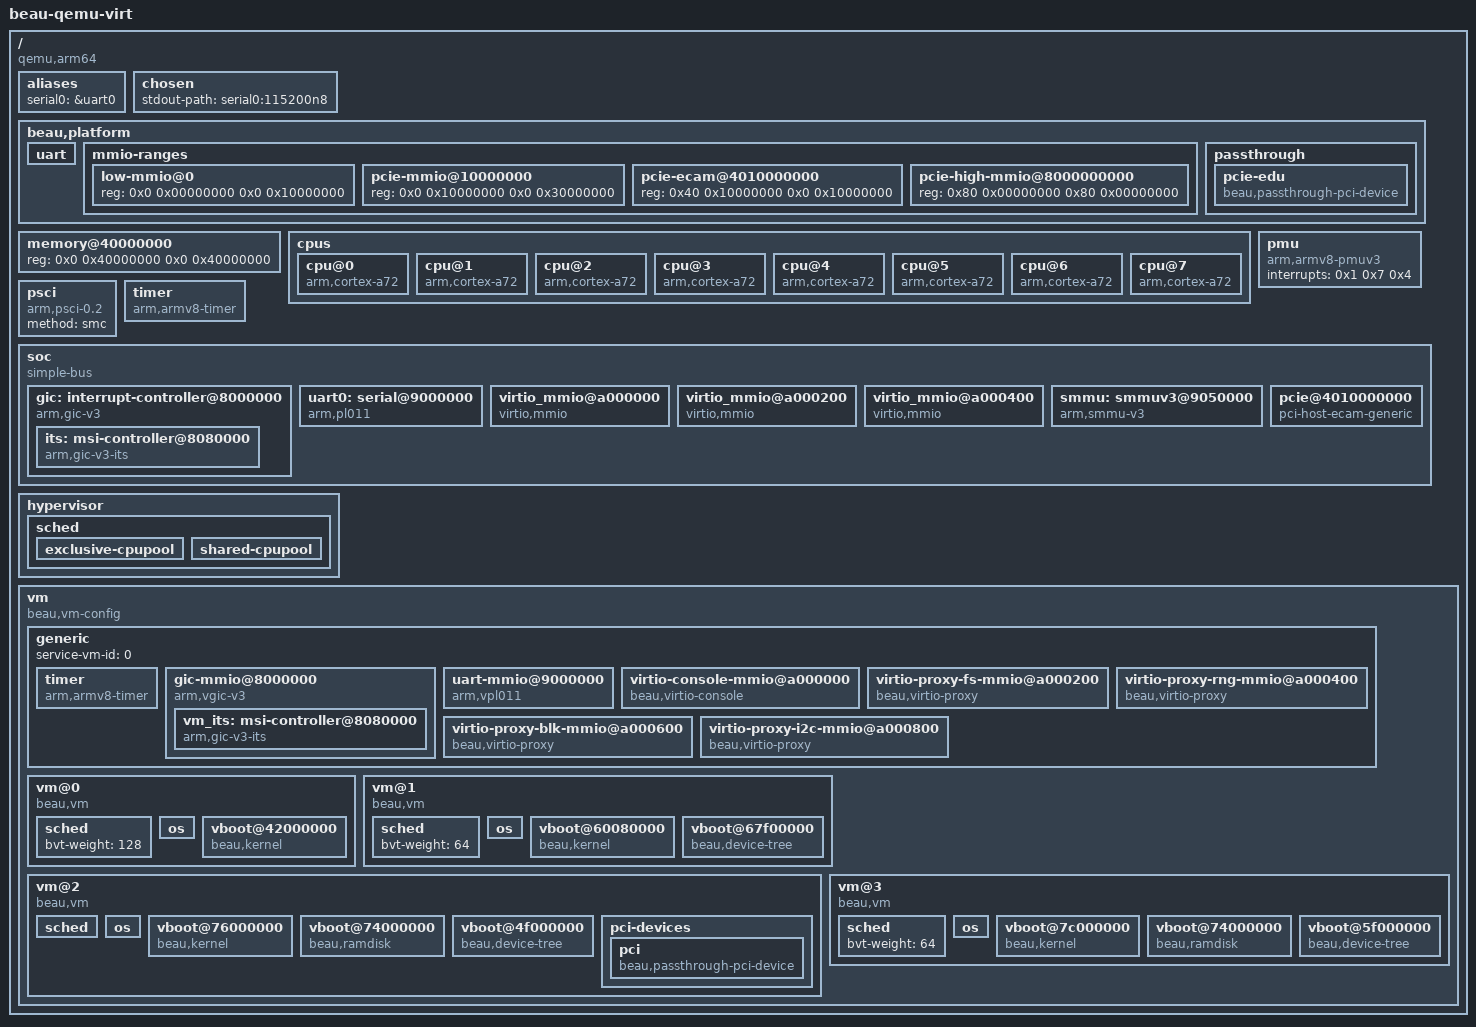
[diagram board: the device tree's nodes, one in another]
/dts-v1/;

/ {
	interrupt-parent = <&gic>;
	#address-cells = <2>;
	#size-cells = <2>;
	compatible = "qemu,arm64", "beau,qemu-static-config";
	model = "beau-qemu-virt";

	aliases {
		serial0 = &uart0;
	};

	chosen {
		stdout-path = "serial0:115200n8";
	};

	beau,platform {
		gic-iidr = <0x43b>;
		guest-cpu-compatible = "arm,cortex-a57";
		vfdt-model = "linux,dummy-virt";
		vfdt-compatible = "linux,dummy-virt";
		service-vm-initrd = <0>;

		uart {
			clock-frequency = <24000000>;
			current-speed = <115200>;
		};

		mmio-ranges {
			#address-cells = <2>;
			#size-cells = <2>;

			low-mmio@0 {
				reg = <0x0 0x00000000 0x0 0x10000000>;
			};

			pcie-mmio@10000000 {
				reg = <0x0 0x10000000 0x0 0x30000000>;
			};

			pcie-ecam@4010000000 {
				reg = <0x40 0x10000000 0x0 0x10000000>;
			};

			pcie-high-mmio@8000000000 {
				reg = <0x80 0x00000000 0x80 0x00000000>;
			};
		};

		passthrough {
			pcie-edu {
				compatible = "beau,passthrough-pci-device",
					     "beau,passthrough-device";
				beau,name = "qemu-pcie-edu";
				beau,owner-vm = <2>;
				beau,stream-id = <0x0008>;
				beau,writable;
			};
		};
	};

	memory@40000000 {
		device_type = "memory";
		reg = <0x0 0x40000000 0x0 0x40000000>;
	};

	cpus {
		#address-cells = <1>;
		#size-cells = <0>;

		cpu@0 {
			device_type = "cpu";
			compatible = "arm,cortex-a72";
			reg = <0>;
			enable-method = "psci";
		};

		cpu@1 {
			device_type = "cpu";
			compatible = "arm,cortex-a72";
			reg = <1>;
			enable-method = "psci";
		};

		cpu@2 {
			device_type = "cpu";
			compatible = "arm,cortex-a72";
			reg = <2>;
			enable-method = "psci";
		};

		cpu@3 {
			device_type = "cpu";
			compatible = "arm,cortex-a72";
			reg = <3>;
			enable-method = "psci";
		};

		cpu@4 {
			device_type = "cpu";
			compatible = "arm,cortex-a72";
			reg = <4>;
			enable-method = "psci";
		};

		cpu@5 {
			device_type = "cpu";
			compatible = "arm,cortex-a72";
			reg = <5>;
			enable-method = "psci";
		};

		cpu@6 {
			device_type = "cpu";
			compatible = "arm,cortex-a72";
			reg = <6>;
			enable-method = "psci";
		};

		cpu@7 {
			device_type = "cpu";
			compatible = "arm,cortex-a72";
			reg = <7>;
			enable-method = "psci";
		};
	};

	pmu {
		compatible = "arm,armv8-pmuv3";
		interrupts = <0x1 0x7 0x4>;
	};

	psci {
		compatible = "arm,psci-0.2";
		method = "smc";
	};

	timer {
		compatible = "arm,armv8-timer";
		interrupts = <0x1 0xd 0x4>,
			     <0x1 0xe 0x4>,
			     <0x1 0xb 0x4>,
			     <0x1 0xa 0x4>;
	};

	soc {
		compatible = "simple-bus";
		#address-cells = <2>;
		#size-cells = <2>;
		ranges;

		gic: interrupt-controller@8000000 {
			compatible = "arm,gic-v3", "arm,gic";
			reg = <0x0 0x08000000 0x0 0x00010000>,
			      <0x0 0x080a0000 0x0 0x00100000>;
			interrupts = <0x1 0x9 0x4>;
			interrupt-controller;
			#interrupt-cells = <3>;
			#address-cells = <2>;
			#size-cells = <2>;
			ranges;

			its: msi-controller@8080000 {
				compatible = "arm,gic-v3-its";
				reg = <0x0 0x08080000 0x0 0x00020000>;
				msi-controller;
			};
		};

		uart0: serial@9000000 {
			compatible = "arm,pl011", "arm,primecell";
			reg = <0x0 0x09000000 0x0 0x00001000>;
			interrupts = <0x0 0x1 0x4>;
			clock-frequency = <24000000>;
		};

		virtio_mmio@a000000 {
			compatible = "virtio,mmio";
			reg = <0x0 0x0a000000 0x0 0x00000200>;
			interrupts = <0x0 0x10 0x1>;
			dma-coherent;
		};

		virtio_mmio@a000200 {
			compatible = "virtio,mmio";
			reg = <0x0 0x0a000200 0x0 0x00000200>;
			interrupts = <0x0 0x11 0x1>;
			dma-coherent;
		};

		virtio_mmio@a000400 {
			compatible = "virtio,mmio";
			reg = <0x0 0x0a000400 0x0 0x00000200>;
			interrupts = <0x0 0x12 0x1>;
			dma-coherent;
		};

		smmu: smmuv3@9050000 {
			compatible = "arm,smmu-v3";
			reg = <0x0 0x09050000 0x0 0x00020000>;
			interrupts = <0x0 0x4a 0x4>,
				     <0x0 0x4b 0x4>,
				     <0x0 0x4c 0x4>,
				     <0x0 0x4d 0x4>;
			#iommu-cells = <1>;
		};

		pcie@4010000000 {
			compatible = "pci-host-ecam-generic";
			device_type = "pci";
			#address-cells = <3>;
			#size-cells = <2>;
			reg = <0x40 0x10000000 0x0 0x10000000>;
			bus-range = <0x0 0xff>;
			msi-map = <0x0 &its 0x0 0x10000>;
			iommu-map = <0x0 &smmu 0x0 0x10000>;
			dma-coherent;
			ranges = <0x01000000 0x0 0x00000000 0x0 0x3eff0000 0x0 0x00010000>,
				 <0x02000000 0x0 0x10000000 0x0 0x10000000 0x0 0x2eff0000>,
				 <0x03000000 0x80 0x00000000 0x80 0x00000000 0x80 0x00000000>;
		};
	};

	hypervisor {
		sched {
			exclusive-cpupool {
				pcpus = <0 1 4 5>;
				policy = "bvt";
			};
			shared-cpupool {
				pcpus = <2 3 6 7>;
				policy = "cbs";
				period = <3000>;
				budget = <1000>;
			};
		};
	};

	vm {
		compatible = "beau,vm-config";
		#address-cells = <1>;
		#size-cells = <0>;

		// Generic VM configuration
		generic {
			#address-cells = <2>;
			#size-cells = <2>;
			service-vm-id = <0>;

			timer {
				compatible = "arm,armv8-timer";
				// Hypervisor Timer
				htimer-ppi = <26>;
				// Virtual Timer
				vtimer-ppi = <27>;
				// Physical Timer
				ptimer-ppi = <30>;
			};

			gic-mmio@8000000 {
				compatible = "arm,vgic-v3";
				reg = <0x0 0x08000000 0x0 0x00010000>,
					  <0x0 0x080a0000 0x0 0x00100000>;
				interrupts = <0x1 0x9 0x4>;
				interrupt-controller;
				#interrupt-cells = <3>;
				#address-cells = <2>;
				#size-cells = <2>;
				ranges;

				vm_its: msi-controller@8080000 {
					compatible = "arm,gic-v3-its";
					reg = <0x0 0x08080000 0x0 0x00020000>;
					msi-controller;
				};
			};

			/*
			 * Guest console frontend policy:
			 *   RTOS  <- vPL011
			 *   Linux <- virtio-console
			 */
			uart-mmio@9000000 {
				compatible = "arm,vpl011";
				reg = <0x0 0x09000000 0x0 0x00001000>;
				interrupts = <0x0 0x1 0x4>;
				clock-frequency = <24000000>;
			};

			virtio-console-mmio@a000000 {
				compatible = "beau,virtio-console", "virtio,mmio";
				reg = <0x0 0x0a000000 0x0 0x00000200>;
				interrupts = <0x0 0x10 0x4>;
			};

			virtio-proxy-fs-mmio@a000200 {
				compatible = "beau,virtio-proxy", "beau,virtio-fs", "virtio,mmio";
				reg = <0x0 0x0a000200 0x0 0x00000200>;
				interrupts = <0x0 0x11 0x4>;
				beau,device-id = <26>;
				beau,frontend-vmid = <3>;
				beau,queue-num = <2>;
				beau,queue-size = <64>;
				beau,pending-num = <4>;
				beau,tag = "proxy-fs";
				beau,throughput = "high";
			};

			virtio-proxy-rng-mmio@a000400 {
				compatible = "beau,virtio-proxy", "beau,virtio-rng", "virtio,mmio";
				reg = <0x0 0x0a000400 0x0 0x00000200>;
				interrupts = <0x0 0x12 0x4>;
				beau,device-id = <4>;
				beau,frontend-vmid = <3>;
				beau,queue-num = <1>;
				beau,queue-size = <64>;
				beau,pending-num = <1>;
				beau,tag = "proxy-rng";
				beau,throughput = "low";
			};

			virtio-proxy-blk-mmio@a000600 {
				compatible = "beau,virtio-proxy", "beau,virtio-blk", "virtio,mmio";
				reg = <0x0 0x0a000600 0x0 0x00000200>;
				interrupts = <0x0 0x13 0x4>;
				beau,device-id = <2>;
				beau,frontend-vmid = <3>;
				beau,queue-num = <1>;
				beau,queue-size = <64>;
				beau,pending-num = <4>;
				beau,tag = "proxy-blk";
				beau,throughput = "high";
			};

			virtio-proxy-i2c-mmio@a000800 {
				compatible = "beau,virtio-proxy", "beau,virtio-i2c", "virtio,mmio";
				reg = <0x0 0x0a000800 0x0 0x00000200>;
				interrupts = <0x0 0x14 0x4>;
				beau,device-id = <34>;
				beau,frontend-vmid = <3>;
				beau,queue-num = <1>;
				beau,queue-size = <64>;
				beau,pending-num = <1>;
				beau,tag = "proxy-i2c";
				beau,throughput = "low";
			};
		};

		/*
		 * 2026-07-08, QEMU cpu-affinity is ordered: entry N is vcpuN's pCPU.
		 * This 4OS layout keeps vCPU0 on an exclusive pCPU and maps
		 * secondary vCPUs to shared pCPUs. VM0 and VM1 intentionally have
		 * 2 vCPUs.
		 */
		vm@0 {
			compatible = "beau,vm";
			reg = <0>;
			#address-cells = <2>;
			#size-cells = <2>;
			beau,name = "Zephyr";
			load-order = "service";
			beau,static-mem = <0x0 0x42000000 0x0 0x06000000>;
			direct-map;
			cpu-affinity = <0 2>;
			guest-flags = "static", "no-fw";
			beau,sve = "disabled";

			sched {
				bvt-weight = <128>;
			};

			os {
				os-name = "Zephyr";
				family = "rtos";
			};

			vboot@42000000 {
				compatible = "beau,kernel", "beau,vboot";
				tag = "Zephyr";
				source = "symbol";
				addr-symbol = "arm64_zephyr_image_start";
				size-source = "symbol";
				size-symbol = "arm64_zephyr_image_size";
				reg = <0x0 0x42000000 0x0 0x0>;
				load-addr = <0x0 0x42000000>;
				entry-addr = <0x0 0x42000000>;
			};
		};

		vm@1 {
			compatible = "beau,vm";
			reg = <1>;
			#address-cells = <2>;
			#size-cells = <2>;
			beau,name = "RT-Thread";
			load-order = "pre-std";
			beau,static-mem = <0x0 0x60000000 0x0 0x08000000>;
			direct-map;
			cpu-affinity = <1 7>;
			guest-flags = "static";
			beau,sve = "disabled";

			sched {
				bvt-weight = <64>;
			};

			os {
				os-name = "RT-Thread";
				family = "rtos";
			};

			vboot@60080000 {
				compatible = "beau,kernel", "beau,vboot";
				tag = "RT-Thread";
				source = "symbol";
				addr-symbol = "arm64_rtthread_image_start";
				size-source = "symbol";
				size-symbol = "arm64_rtthread_image_size";
				reg = <0x0 0x60080000 0x0 0x0>;
				load-addr = <0x0 0x60080000>;
				entry-addr = <0x0 0x60080000>;
			};

			vboot@67f00000 {
				compatible = "beau,device-tree", "beau,vboot";
				tag = "dtb-rtthread";
				source = "symbol";
				addr-symbol = "arm64_beau_rtthread_dtb_start";
				size-source = "symbol";
				size-symbol = "arm64_beau_rtthread_dtb_size";
				reg = <0x0 0x67f00000 0x0 0x0>;
			};
		};

		vm@2 {
			compatible = "beau,vm";
			reg = <2>;
			#address-cells = <2>;
			#size-cells = <2>;
			beau,name = "Linux-2";
			load-order = "pre-std";
			beau,static-mem = <0x0 0x48000000 0x0 0x08000000>;
			direct-map;
			cpu-affinity = <4 2 3 6>;
			guest-flags = "static";
			beau,sve = "enabled";
			beau,sve-vl-bits = <128>;

			sched {
				bvt-weight = <128>;
				bvt-warp-value = <8>;
				bvt-warp-limit = <2>;
				bvt-unwarp-period = <4>;
			};

			os {
				os-name = "Linux-2";
				family = "linux";
			};

			vboot@76000000 {
				compatible = "beau,kernel", "beau,vboot";
				tag = "Linux-VM2";
				reg = <0x0 0x76000000 0x0 0x0>;
				size-source = "symbol";
				size-symbol = "BEAU_LINUX_VM2_IMAGE_SIZE";
				load-addr = <0x0 0x48080000>;
				entry-addr = <0x0 0x48080000>;
				bootargs = "console=hvc0 rdinit=/init loglevel=4";
			};

			vboot@74000000 {
				compatible = "beau,ramdisk", "beau,vboot";
				tag = "Initramfs";
				reg = <0x0 0x74000000 0x0 0x0>;
				size-source = "symbol";
				size-symbol = "BEAU_LINUX_INITRAMFS_SIZE";
				load-addr = <0x0 0x4c000000>;
			};

			vboot@4f000000 {
				compatible = "beau,device-tree", "beau,vboot";
				tag = "dtb-vm2";
				source = "symbol";
				addr-symbol = "arm64_beau_linux_vm2_dtb_start";
				size-source = "symbol";
				size-symbol = "arm64_beau_linux_vm2_dtb_size";
				reg = <0x0 0x4f000000 0x0 0x0>;
			};

			pci-devices {
				pci {
					compatible = "beau,passthrough-pci-device";
					beau,pbdf = <0x0008>;
					beau,vbdf = <0x0008>;
					beau,pbar-base = <0x0 0x10000000>;
					beau,vbar-base = <0x0 0x80000000>;
				};
			};
		};

		vm@3 {
			compatible = "beau,vm";
			reg = <3>;
			#address-cells = <2>;
			#size-cells = <2>;
			beau,name = "Linux-3";
			load-order = "pre-std";
			beau,static-mem = <0x0 0x58000000 0x0 0x08000000>;
			direct-map;
			cpu-affinity = <5 2 3 7>;
			guest-flags = "static";
			beau,sve = "enabled";
			beau,sve-vl-bits = <128>;

			sched {
				bvt-weight = <64>;
			};

			os {
				os-name = "Linux-3";
				family = "linux";
			};

			vboot@7c000000 {
				compatible = "beau,kernel", "beau,vboot";
				tag = "Linux-VM3";
				reg = <0x0 0x7c000000 0x0 0x0>;
				size-source = "symbol";
				size-symbol = "BEAU_LINUX_VM3_IMAGE_SIZE";
				load-addr = <0x0 0x58080000>;
				entry-addr = <0x0 0x58080000>;
				bootargs = "console=hvc0 rdinit=/init loglevel=4";
			};

			vboot@74000000 {
				compatible = "beau,ramdisk", "beau,vboot";
				tag = "Initramfs";
				reg = <0x0 0x74000000 0x0 0x0>;
				size-source = "symbol";
				size-symbol = "BEAU_LINUX_INITRAMFS_SIZE";
				load-addr = <0x0 0x5c000000>;
			};

			vboot@5f000000 {
				compatible = "beau,device-tree", "beau,vboot";
				tag = "dtb-vm3";
				source = "symbol";
				addr-symbol = "arm64_beau_linux_vm3_dtb_start";
				size-source = "symbol";
				size-symbol = "arm64_beau_linux_vm3_dtb_size";
				reg = <0x0 0x5f000000 0x0 0x0>;
			};
		};
	};
};
